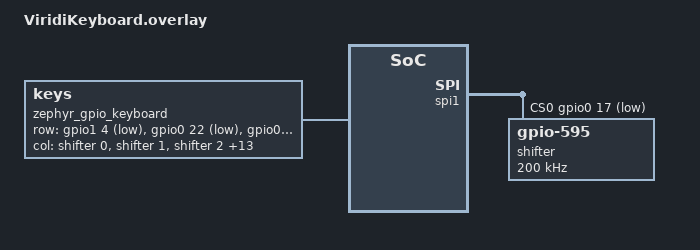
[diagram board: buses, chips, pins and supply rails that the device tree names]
#include "physical_layouts.dtsi"
// Включаем SPI2 для 74HC595
&spi1 {
    status = "okay";

    // SCK, MOSI — настраиваются в DTSI, CS — свой пин
    cs-gpios = <&gpio0 17 GPIO_ACTIVE_LOW>; // STCP

    shifter: 595@0 {
        compatible = "zmk,gpio-595";
        status = "okay";

        gpio-controller;
        #gpio-cells = <2>;
        ngpios = <16>;

        spi-max-frequency = <200000>;
        reg = <0>;
    };
};

// Определяем матрицу клавиатуры
/ {
    zephyr_gpio_keyboard: gpio_keys {
        compatible = "zmk,keys";

        // Строки — подключены напрямую к пинам
        row-gpios = <&gpio1 4 GPIO_ACTIVE_LOW>,   // P1.04 (Row 0)
                    <&gpio0 22 GPIO_ACTIVE_LOW>,  // P0.22 (Row 1)
                    <&gpio0 20 GPIO_ACTIVE_LOW>,  // P0.20 (Row 2)
                    <&gpio1 0 GPIO_ACTIVE_LOW>,   // P1.00 (Row 3)
                    <&gpio0 24 GPIO_ACTIVE_LOW>,  // P0.24 (Row 4)
                    <&gpio0 11 GPIO_ACTIVE_LOW>;  // P0.11 (Row 5)

        // Столбцы — через 74HC595
        col-gpios = <&shifter 0 GPIO_ACTIVE_HIGH>,
                    <&shifter 1 GPIO_ACTIVE_HIGH>,
                    <&shifter 2 GPIO_ACTIVE_HIGH>,
                    <&shifter 3 GPIO_ACTIVE_HIGH>,
                    <&shifter 4 GPIO_ACTIVE_HIGH>,
                    <&shifter 5 GPIO_ACTIVE_HIGH>,
                    <&shifter 6 GPIO_ACTIVE_HIGH>,
                    <&shifter 7 GPIO_ACTIVE_HIGH>,
                    <&shifter 8 GPIO_ACTIVE_HIGH>,
                    <&shifter 9 GPIO_ACTIVE_HIGH>,
                    <&shifter 10 GPIO_ACTIVE_HIGH>,
                    <&shifter 11 GPIO_ACTIVE_HIGH>,
                    <&shifter 12 GPIO_ACTIVE_HIGH>,
                    <&shifter 13 GPIO_ACTIVE_HIGH>,
                    <&shifter 14 GPIO_ACTIVE_HIGH>,
                    <&shifter 15 GPIO_ACTIVE_HIGH>;

        // Параметры опроса
        debounce-delay-ms = <5>;
        poll-delay-ms = <10>;
        poll-interval-ms = <33>;

        // Диоды: катоды к строкам, аноды к столбцам → COL2ROW
        zmk,matrix-diode-polarities = /bits/ 8 <1>;

        // Трансформация матрицы
        matrix-transform = <&default_transform>;
    };

    // Определение трансформации матрицы (как отображаются ключи)
    default_transform: matrix_transform {
        compatible = "zmk,matrix-transform";
        rows = <6>;
        columns = <16>;

        // Порядок: слева направо, сверху вниз
        // Каждое число — это индекс ключа (0, 1, 2, ...)
        map = <
            0   1   2   3   4   5   6   7   8   9  10  11  12  13  14  15
           16  17  18  19  20  21  22  23  24  25  26  27  28  29  30  31
           32  33  34  35  36  37  38  39  40  41  42  43  44  45  46  47
           48  49  50  51  52  53  54  55  56  57  58  59  60  61  62  63
           64  65  66  67  68  69  70  71  72  73  74  75  76  77  78  79
           80  81  82  83  84  85  86  87  88  89  90  91  92  93  94  95
        >;
    };
};





